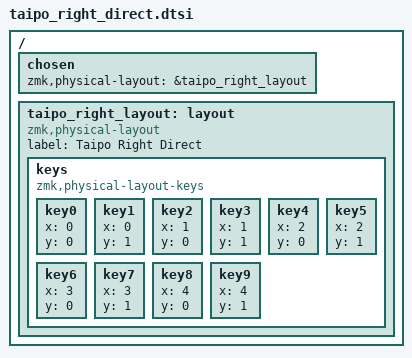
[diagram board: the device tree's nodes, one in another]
/ {
    chosen {
        zmk,physical-layout = &taipo_right_layout;
    };

    taipo_right_layout: layout {
        compatible = "zmk,physical-layout";
        label = "Taipo Right Direct";

        keys {
            compatible = "zmk,physical-layout-keys";

            key0 { x = 0; y = 0; };
            key1 { x = 0; y = 1; };

            key2 { x = 1; y = 0; };
            key3 { x = 1; y = 1; };

            key4 { x = 2; y = 0; };
            key5 { x = 2; y = 1; };

            key6 { x = 3; y = 0; };
            key7 { x = 3; y = 1; };

            key8 { x = 4; y = 0; };
            key9 { x = 4; y = 1; };
        };
    };
};
